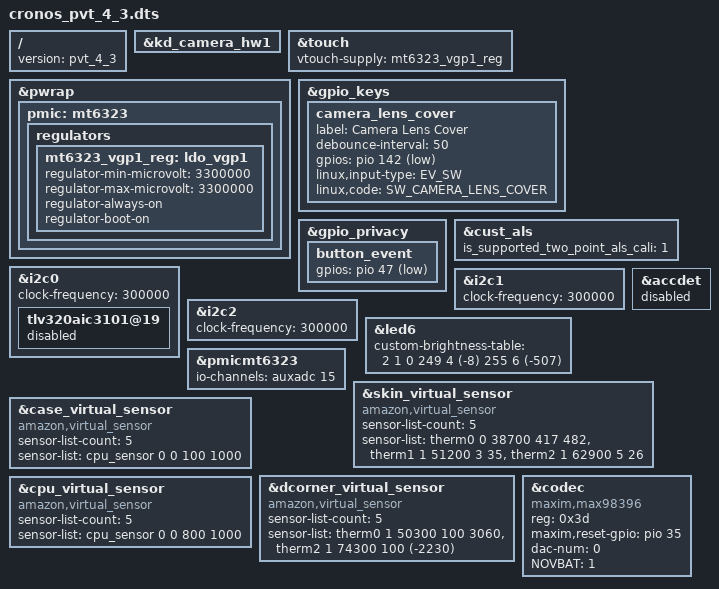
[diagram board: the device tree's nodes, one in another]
/*
 * Copyright (C) 2021 Amazon.com
 *
 * This program is free software: you can redistribute it and/or modify
 * it under the terms of the GNU General Public License version 2 as
 * published by the Free Software Foundation.
 *
 * This program is distributed in the hope that it will be useful,
 * but WITHOUT ANY WARRANTY; without even the implied warranty of
 * MERCHANTABILITY or FITNESS FOR A PARTICULAR PURPOSE. See the
 * GNU General Public License for more details.
 *
 */

/dts-v1/;

#include <dt-bindings/input/input.h>
#include "cronos.dtsi"

/ {
	version = "pvt_4_3";
};

&kd_camera_hw1 {
        /delete-property/ reg-vcamd-supply;
};

&touch {
	vtouch-supply = <&mt6323_vgp1_reg>;
};

&pwrap {
	pmic: mt6323 {
		regulators {
			mt6323_vgp1_reg: ldo_vgp1 {
				regulator-min-microvolt = <3300000>;
				regulator-max-microvolt = <3300000>;
				regulator-always-on;
				regulator-boot-on;
			};
		};
	};
};

&gpio_keys {
	camera_lens_cover {
		label = "Camera Lens Cover";
		debounce-interval = <50>;
		gpios = <&pio 142 GPIO_ACTIVE_LOW>;
		linux,input-type = <EV_SW>;
		linux,code = <SW_CAMERA_LENS_COVER>;
	};
};

&gpio_privacy {
	button_event {
		gpios = <&pio 47 GPIO_ACTIVE_LOW>;
	};
};

&cust_als {
	is_supported_two_point_als_cali = <1>;
};

&i2c0 {
	clock-frequency = <300000>;
	tlv320aic3101@19 {
		status = "disabled";
	};
};

&i2c1 {
	clock-frequency = <300000>;
};

&i2c2 {
	clock-frequency = <300000>;
	/delete-node/ focaltech_ts@38;
	/delete-node/ tmp103-sensor@71;
	/delete-node/ tmp103-sensor@72;
	/delete-node/ tmp103-sensor@73;
};

&accdet {
	status = "disabled";
};

&led6 {
	custom-brightness-table = <2 1 0
				249 4 (-8)
				255 6 (-507)>;
};

&pmicmt6323 {
	io-channels = <&auxadc 15>;
	io-channel-names = "power-channel";
};

&skin_virtual_sensor {
	compatible = "amazon,virtual_sensor";
	#thermal-sensor-cells = <0>;

	sensor-list-count = <5>;
	sensor-list = <&therm0 0 38700 417 482>,
	              <&therm1 1 51200 3 35>,
	              <&therm2 1 62900 5 26>;
};

&case_virtual_sensor {
	compatible = "amazon,virtual_sensor";
	#thermal-sensor-cells = <0>;

	sensor-list-count = <5>;
	sensor-list = <&cpu_sensor 0 0 100 1000>;
};

&dcorner_virtual_sensor {
	compatible = "amazon,virtual_sensor";
	#thermal-sensor-cells = <0>;

	sensor-list-count = <5>;
	sensor-list = <&therm0 1 50300 100 3060>,
	              <&therm2 1 74300 100 (-2230)>;
};

&cpu_virtual_sensor {
	compatible = "amazon,virtual_sensor";
	#thermal-sensor-cells = <0>;

	sensor-list-count = <5>;
	sensor-list = <&cpu_sensor 0 0 800 1000>;
};

&codec {
	compatible = "maxim,max98396";
	reg = <0x3d>;
	/delete-property/ hw_mode;
	/delete-property/ depop_mode;
	/delete-property/ realtek,amp-gpio;
	/delete-property/ pinctrl-names;
	/delete-property/ pinctrl-0;
	/delete-property/ pinctrl-1;
	maxim,reset-gpio = <&pio 35 GPIO_ACTIVE_HIGH>;
	dac-num = <0>;
	NOVBAT = <1>;
	phandle = <0x4D>; // Force phandle to be created for u-boot to link sound card.
	status = "okay";
};
